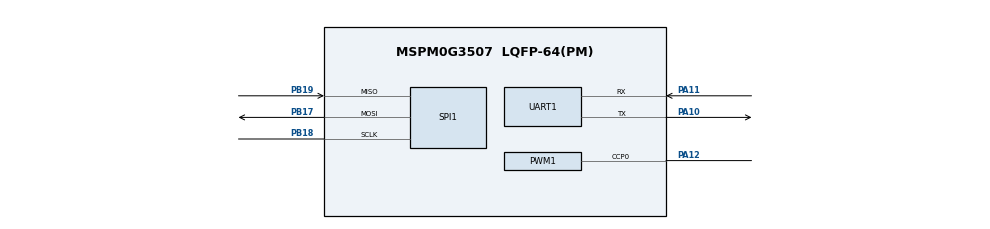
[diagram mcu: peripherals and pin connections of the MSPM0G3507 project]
/**
 * These arguments were used when this file was generated. They will be automatically applied on subsequent loads
 * via the GUI or CLI. Run CLI with '--help' for additional information on how to override these arguments.
 * @cliArgs --device "MSPM0G350X" --part "Default" --package "LQFP-64(PM)" --product "mspm0_sdk@2.10.00.04"
 * @v2CliArgs --device "MSPM0G3507" --package "LQFP-64(PM)" --product "mspm0_sdk@2.10.00.04"
 * @versions {"tool":"1.26.2+4477"}
 */

/**
 * Import the modules used in this configuration.
 */
const GPIO   = scripting.addModule("/ti/driverlib/GPIO", {}, false);
const GPIO1  = GPIO.addInstance();
const GPIO2  = GPIO.addInstance();
const GPIO3  = GPIO.addInstance();
const PWM    = scripting.addModule("/ti/driverlib/PWM", {}, false);
const PWM1   = PWM.addInstance();
const SPI    = scripting.addModule("/ti/driverlib/SPI", {}, false);
const SPI1   = SPI.addInstance();
const SYSCTL = scripting.addModule("/ti/driverlib/SYSCTL");
const TIMER  = scripting.addModule("/ti/driverlib/TIMER", {}, false);
const TIMER1 = TIMER.addInstance();
const TIMER2 = TIMER.addInstance();
const UART   = scripting.addModule("/ti/driverlib/UART", {}, false);
const UART1  = UART.addInstance();

/**
 * Write custom configuration values to the imported modules.
 */
GPIO1.$name                                 = "CS";
GPIO1.associatedPins[0].$name               = "CS1";
GPIO1.associatedPins[0].initialValue        = "SET";
GPIO1.associatedPins[0].assignedPort        = "PORTA";
GPIO1.associatedPins[0].assignedPortSegment = "Lower";
GPIO1.associatedPins[0].assignedPin         = "8";

const Board = scripting.addModule("/ti/driverlib/Board", {}, false);

GPIO2.$name                              = "ALERT";
GPIO2.associatedPins[0].$name            = "INA229_ALERT";
GPIO2.associatedPins[0].direction        = "INPUT";
GPIO2.associatedPins[0].interruptEn      = true;
GPIO2.associatedPins[0].polarity         = "FALL";
GPIO2.associatedPins[0].internalResistor = "PULL_UP";

GPIO3.$name                               = "GPIO_GRP_0";
GPIO3.associatedPins[0].$name             = "PIN_0";
GPIO3.associatedPins[0].launchPadShortcut = "Button3En";
GPIO3.associatedPins[0].interruptEn       = true;
GPIO3.associatedPins[0].polarity          = "RISE";
GPIO3.associatedPins[0].internalResistor  = "PULL_DOWN";

PWM1.$name                      = "PWM_0";
PWM1.timerCount                 = 320;
PWM1.ccIndex                    = [0];
PWM1.PWM_CHANNEL_0.$name        = "ti_driverlib_pwm_PWMTimerCC0";
PWM1.PWM_CHANNEL_0.dutyCycle    = 30;
PWM1.ccp0PinConfig.$name        = "ti_driverlib_gpio_GPIOPinGeneric5";
PWM1.peripheral.ccp0Pin.$assign = "PA12";

SPI1.$name                      = "SPI_0";
SPI1.enableDMAEvent1            = false;
SPI1.enableDMAEvent2            = false;
SPI1.spiClkSrc                  = "MFCLK";
SPI1.spiClkDiv                  = "4";
SPI1.frameFormat                = "MOTO3";
SPI1.chipSelect                 = [];
SPI1.phase                      = "1";
SPI1.targetBitRate              = 500000;
SPI1.rxFifoThreshold            = "DL_SPI_RX_FIFO_LEVEL_ONE_FRAME";
SPI1.txFifoThreshold            = "DL_SPI_TX_FIFO_LEVEL_ONE_FRAME";
SPI1.sclkPinConfig.$name        = "ti_driverlib_gpio_GPIOPinGeneric0";
SPI1.mosiPinConfig.$name        = "ti_driverlib_gpio_GPIOPinGeneric1";
SPI1.misoPinConfig.$name        = "ti_driverlib_gpio_GPIOPinGeneric2";
SPI1.peripheral.$assign         = "SPI0";
SPI1.peripheral.sclkPin.$assign = "PB18";
SPI1.peripheral.mosiPin.$assign = "PB17";
SPI1.peripheral.misoPin.$assign = "PB19";

SYSCTL.forceDefaultClkConfig = true;
SYSCTL.MFCLKEn               = true;

TIMER1.$name              = "TIMER_0";
TIMER1.timerClkSrc        = "LFCLK";
TIMER1.timerMode          = "PERIODIC_UP";
TIMER1.timerStartTimer    = true;
TIMER1.interrupts         = ["OVERFLOW"];
TIMER1.timerPeriod        = "10 ms";
TIMER1.peripheral.$assign = "TIMA0";

TIMER2.$name              = "TIMER_1";
TIMER2.timerClkSrc        = "LFCLK";
TIMER2.timerMode          = "PERIODIC_UP";
TIMER2.timerStartTimer    = true;
TIMER2.interrupts         = ["OVERFLOW"];
TIMER2.timerPeriod        = "2 s";
TIMER2.peripheral.$assign = "TIMA1";

UART1.$name                    = "UART_0";
UART1.profile                  = "CONFIG_PROFILE_2";
UART1.peripheral.$assign       = "UART0";
UART1.peripheral.rxPin.$assign = "PA11";
UART1.peripheral.txPin.$assign = "PA10";
UART1.txPinConfig.$name        = "ti_driverlib_gpio_GPIOPinGeneric3";
UART1.rxPinConfig.$name        = "ti_driverlib_gpio_GPIOPinGeneric4";

/**
 * Pinmux solution for unlocked pins/peripherals. This ensures that minor changes to the automatic solver in a future
 * version of the tool will not impact the pinmux you originally saw.  These lines can be completely deleted in order to
 * re-solve from scratch.
 */
GPIO1.associatedPins[0].pin.$suggestSolution = "PA8";
Board.peripheral.$suggestSolution            = "DEBUGSS";
Board.peripheral.swclkPin.$suggestSolution   = "PA20";
Board.peripheral.swdioPin.$suggestSolution   = "PA19";
GPIO2.associatedPins[0].pin.$suggestSolution = "PB13";
GPIO3.associatedPins[0].pin.$suggestSolution = "PB21";
PWM1.peripheral.$suggestSolution             = "TIMG0";
SYSCTL.peripheral.$suggestSolution           = "SYSCTL";
